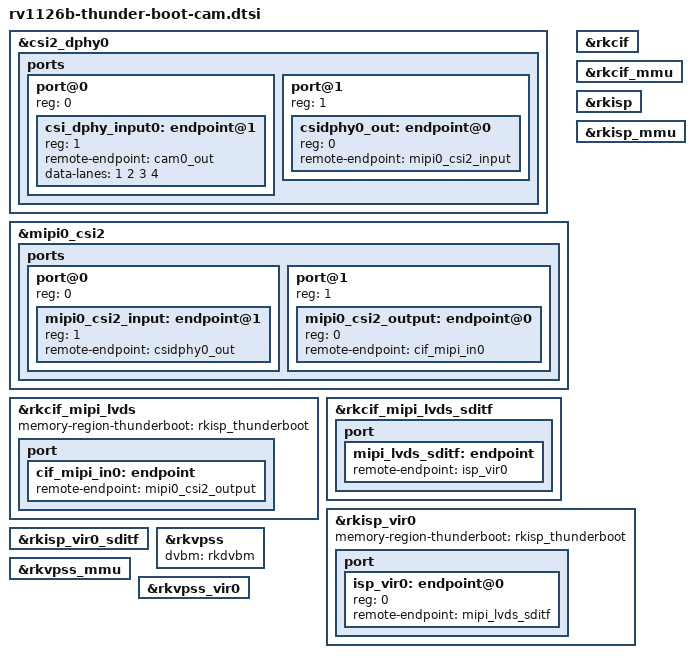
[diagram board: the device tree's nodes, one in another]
// SPDX-License-Identifier: (GPL-2.0+ OR MIT)
/*
 * Copyright (c) 2025 Rockchip Electronics Co., Ltd.
 *
 */

&csi2_dphy0 {
	status = "okay";

	ports {
		#address-cells = <1>;
		#size-cells = <0>;
		port@0 {
			reg = <0>;
			#address-cells = <1>;
			#size-cells = <0>;

			csi_dphy_input0: endpoint@1 {
				reg = <1>;
				remote-endpoint = <&cam0_out>;
				data-lanes = <1 2 3 4>;
			};
		};
		port@1 {
			reg = <1>;
			#address-cells = <1>;
			#size-cells = <0>;

			csidphy0_out: endpoint@0 {
				reg = <0>;
				remote-endpoint = <&mipi0_csi2_input>;
			};
		};
	};
};

&mipi0_csi2 {
	status = "okay";

	ports {
		#address-cells = <1>;
		#size-cells = <0>;

		port@0 {
			reg = <0>;
			#address-cells = <1>;
			#size-cells = <0>;

			mipi0_csi2_input: endpoint@1 {
				reg = <1>;
				remote-endpoint = <&csidphy0_out>;
			};
		};

		port@1 {
			reg = <1>;
			#address-cells = <1>;
			#size-cells = <0>;

			mipi0_csi2_output: endpoint@0 {
				reg = <0>;
				remote-endpoint = <&cif_mipi_in0>;
			};
		};
	};
};

&rkcif {
	status = "okay";
};

&rkcif_mipi_lvds {
	status = "okay";
	memory-region-thunderboot = <&rkisp_thunderboot>;

	port {
		cif_mipi_in0: endpoint {
			remote-endpoint = <&mipi0_csi2_output>;
		};
	};
};

&rkcif_mipi_lvds_sditf {
	status = "okay";

	port {
		mipi_lvds_sditf: endpoint {
			remote-endpoint = <&isp_vir0>;
		};
	};
};

&rkcif_mmu {
	status = "okay";
};

&rkisp {
	status = "okay";
};

&rkisp_mmu {
	status = "okay";
};

&rkisp_vir0 {
	status = "okay";
	memory-region-thunderboot = <&rkisp_thunderboot>;

	port {
		#address-cells = <1>;
		#size-cells = <0>;

		isp_vir0: endpoint@0 {
			reg = <0>;
			remote-endpoint = <&mipi_lvds_sditf>;
		};
	};
};

&rkisp_vir0_sditf {
	status = "okay";
};

&rkvpss {
	status = "okay";
	dvbm = <&rkdvbm>;
};

&rkvpss_mmu {
	status = "okay";
};

&rkvpss_vir0 {
	status = "okay";
};
